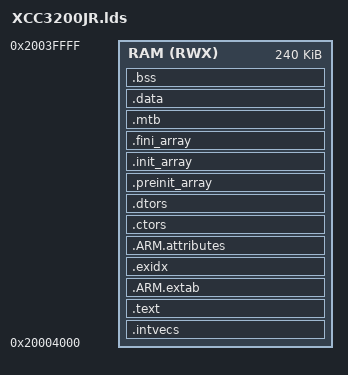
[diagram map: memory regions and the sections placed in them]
/* Generated by LinkerScriptGenerator [http://visualgdb.com/tools/LinkerScriptGenerator]
 * Target: XCC3200JR
 * The file is provided under the BSD license.
 */

ENTRY(ResetISR)

/* The region between 0x20000000 and 0x20004000 is used by the bootloader and cannot contain any initialized data.
 * If out of memory, you can modify the script to place some uninitialized variables or heap/stack there. */
MEMORY
{
	RAM (RWX) : ORIGIN = 0x20004000, LENGTH = 240K
}

_estack = 0x20040000;

SECTIONS
{
	.intvecs :
	{
		. = ALIGN(4);
		KEEP(*(.intvecs))
		. = ALIGN(4);
	} > RAM

	.text :
	{
		. = ALIGN(4);
		_stext = .;

		*(.text)
		*(.text*)
		*(.rodata)
		*(.rodata*)
		*(.glue_7)
		*(.glue_7t)
		*(.eh_frame)
		KEEP(*(.init))
		KEEP(*(.fini))
		. = ALIGN(4);
		_etext = .;

	} > RAM

	.ARM.extab :
	{
		. = ALIGN(4);
		*(.ARM.extab)
		*(.gnu.linkonce.armextab.*)
		. = ALIGN(4);
	} > RAM

	.exidx :
	{
		. = ALIGN(4);
		PROVIDE(__exidx_start__ = .);
		*(.ARM.exidx*)
		. = ALIGN(4);
		PROVIDE(__exidx_end__ = .);
	} > RAM

	.ARM.attributes :
	{
		*(.ARM.attributes)
	} > RAM

	.ctors :
	{
		. = ALIGN(4);
		__CTOR_LIST__ = .;
		KEEP(*crtbegin.o(.ctors))
		KEEP(*(EXCLUDE_FILE (*crtend.o ) .ctors))
		KEEP(*(SORT(.ctors.*)))
		KEEP(*(.ctors*))
		. = ALIGN(4);
		__CTOR_END__ = .;
	} > RAM

	.dtors :
	{
		. = ALIGN(4);
		__DTOR_LIST__ = .;
		KEEP(*crtbegin.o(.dtors))
		KEEP(*(EXCLUDE_FILE (*crtend.o ) .dtors))
		KEEP(*(SORT(.dtors.*)))
		KEEP(*(.dtors*))
		. = ALIGN(4);
		__DTOR_END__ = .;
	} > RAM

	.preinit_array :
	{
		PROVIDE(__preinit_array_start__ = .);
		KEEP(*(.preinit_array*))
		PROVIDE(__preinit_array_end__ = .);
	} > RAM

	.init_array :
	{
		PROVIDE(__init_array_start__ = .);
		KEEP(*(SORT(.init_array.*)))
		KEEP(*(.init_array*))
		PROVIDE(__init_array_end__ = .);
	} > RAM

	.fini_array :
	{
		PROVIDE(__fini_array_start__ = .);
		KEEP(*(.fini_array*))
		KEEP(*(SORT(.fini_array.*)))
		PROVIDE(__fini_array_end__ = .);
	} > RAM

	.mtb :
	{
		. = ALIGN(8);
		_mtb_start = .;
		KEEP(*(.mtb_buf))
		. = ALIGN(8);
		_mtb_end = .;
	} > RAM

	.data :
	{
		. = ALIGN(4);

		_sdata = .;

		PROVIDE(__data_start__ = _sdata);
		*(.data)
		*(.data*)
		. = ALIGN(4);
		_edata = .;

		PROVIDE(__data_end__ = _edata);
	} > RAM

	.bss :
	{
		. = ALIGN(4);
		_sbss = .;

		PROVIDE(__bss_start__ = _sbss);
		*(.bss)
		*(.bss*)
		*(COMMON)
		. = ALIGN(4);
		_ebss = .;

		PROVIDE(__bss_end__ = _ebss);
	} > RAM

	PROVIDE(end = .);

}

